# MKV31F51212 register map
Vendor: Freescale Semiconductor, Inc.; Series: Kinetis_V; File version: 1.6
CPU: CM4 r0p1, little endian, no MPU, FPU, VTOR, 4 interrupt priority bits
Registers are 32-bit, read-write, reset 0x0 unless marked. A register's access mark holds for its fields unless they carry their own. Offsets are from the block's base; [hi:lo] are bit positions; {n}, {i} and the like mark numbered series.

## FTFA_FlashConfig — Flash configuration field
Base 0x00000400; register names take the prefix NV_
0x00 BACKKEY3 8-bit ro reset 0xFF — Backdoor Comparison Key 3.
  [7:0] KEY — Backdoor Comparison Key.
0x01 BACKKEY2 8-bit ro reset 0xFF — Backdoor Comparison Key 2.
  [7:0] KEY — Backdoor Comparison Key.
0x02 BACKKEY1 8-bit ro reset 0xFF — Backdoor Comparison Key 1.
  [7:0] KEY — Backdoor Comparison Key.
0x03 BACKKEY0 8-bit ro reset 0xFF — Backdoor Comparison Key 0.
  [7:0] KEY — Backdoor Comparison Key.
0x04 BACKKEY7 8-bit ro reset 0xFF — Backdoor Comparison Key 7.
  [7:0] KEY — Backdoor Comparison Key.
0x05 BACKKEY6 8-bit ro reset 0xFF — Backdoor Comparison Key 6.
  [7:0] KEY — Backdoor Comparison Key.
0x06 BACKKEY5 8-bit ro reset 0xFF — Backdoor Comparison Key 5.
  [7:0] KEY — Backdoor Comparison Key.
0x07 BACKKEY4 8-bit ro reset 0xFF — Backdoor Comparison Key 4.
  [7:0] KEY — Backdoor Comparison Key.
0x08 FPROT3 8-bit ro reset 0xFF — Non-volatile P-Flash Protection 1 - Low Register
  [7:0] PROT — P-Flash Region Protect
0x09 FPROT2 8-bit ro reset 0xFF — Non-volatile P-Flash Protection 1 - High Register
  [7:0] PROT — P-Flash Region Protect
0x0A FPROT1 8-bit ro reset 0xFF — Non-volatile P-Flash Protection 0 - Low Register
  [7:0] PROT — P-Flash Region Protect
0x0B FPROT0 8-bit ro reset 0xFF — Non-volatile P-Flash Protection 0 - High Register
  [7:0] PROT — P-Flash Region Protect
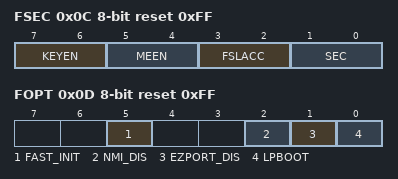
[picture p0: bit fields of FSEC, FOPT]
0x0C FSEC 8-bit ro reset 0xFF — Non-volatile Flash Security Register
  [7:6] KEYEN — Backdoor Key Security Enable
    2=Backdoor key access enabled; 3=Backdoor key access disabled
  [5:4] MEEN
    2=Mass erase is disabled; 3=Mass erase is enabled
  [3:2] FSLACC — Freescale Failure Analysis Access Code
    2=Freescale factory access denied; 3=Freescale factory access granted
  [1:0] SEC — Flash Security
    2=MCU security status is unsecure; 3=MCU security status is secure
0x0D FOPT 8-bit ro reset 0xFF — Non-volatile Flash Option Register
  [5] FAST_INIT
    0=Slower initialization; 1=Fast Initialization
  [2] NMI_DIS
    0=NMI interrupts are always blocked; 1=NMI_b pin/interrupts reset default to enabled
  [1] EZPORT_DIS
    0=EzPort operation is disabled; 1=EzPort operation is enabled
  [0] LPBOOT
    0=Low-power boot; 1=Normal boot

## DMAMUX — DMA channel multiplexor
Base 0x40021000; register names take the prefix DMAMUX_
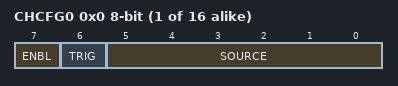
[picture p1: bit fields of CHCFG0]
{0x0+i} CHCFG{i} (i=0..15) 8-bit — Channel Configuration register
  [7] ENBL — DMA Channel Enable
    0=DMA channel is disabled. This mode is primarily used during configuration of the DMAMux. The DMA has separate channel enables/disables, which should be used to disable or reconfigure a DMA channel.; 1=DMA channel is enabled
  [6] TRIG — DMA Channel Trigger Enable
    0=Triggering is disabled. If triggering is disabled and ENBL is set, the DMA Channel will simply route the specified source to the DMA channel. (Normal mode); 1=Triggering is enabled. If triggering is enabled and ENBL is set, the DMAMUX is in Periodic Trigger mode.
  [5:0] SOURCE — DMA Channel Source (Slot)

## DAC0 — 12-Bit Digital-to-Analog Converter
Base 0x4003F000; register names take the prefix DAC0_
{0x0+2i} DAT{i}L (i=0..15) 8-bit — DAC Data Low Register
  [7:0] DATA0
{0x1+2i} DAT{i}H (i=0..15) 8-bit — DAC Data High Register
  [3:0] DATA1
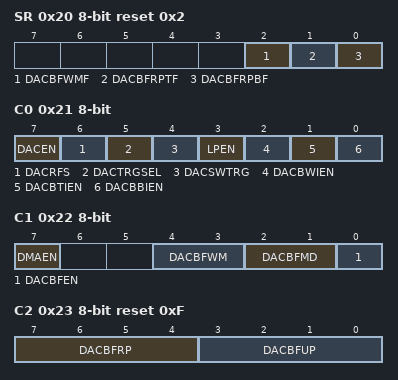
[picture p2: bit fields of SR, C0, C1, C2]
0x20 SR 8-bit reset 0x2 — DAC Status Register
  [2] DACBFWMF — DAC Buffer Watermark Flag
    0=The DAC buffer read pointer has not reached the watermark level; 1=The DAC buffer read pointer has reached the watermark level
  [1] DACBFRPTF — DAC Buffer Read Pointer Top Position Flag
    0=The DAC buffer read pointer is not zero; 1=The DAC buffer read pointer is zero
  [0] DACBFRPBF — DAC Buffer Read Pointer Bottom Position Flag
    0=The DAC buffer read pointer is not equal to C2[DACBFUP]; 1=The DAC buffer read pointer is equal to C2[DACBFUP]
0x21 C0 8-bit — DAC Control Register
  [7] DACEN — DAC Enable
    0=The DAC system is disabled; 1=The DAC system is enabled
  [6] DACRFS — DAC Reference Select
    0=The DAC selects DACREF_1 as the reference voltage; 1=The DAC selects DACREF_2 as the reference voltage
  [5] DACTRGSEL — DAC Trigger Select
    0=The DAC hardware trigger is selected; 1=The DAC software trigger is selected
  [4] DACSWTRG wo — DAC Software Trigger
    0=The DAC soft trigger is not valid; 1=The DAC soft trigger is valid
  [3] LPEN — DAC Low Power Control
    0=High-Power mode; 1=Low-Power mode
  [2] DACBWIEN — DAC Buffer Watermark Interrupt Enable
    0=The DAC buffer watermark interrupt is disabled; 1=The DAC buffer watermark interrupt is enabled
  [1] DACBTIEN — DAC Buffer Read Pointer Top Flag Interrupt Enable
    0=The DAC buffer read pointer top flag interrupt is disabled; 1=The DAC buffer read pointer top flag interrupt is enabled
  [0] DACBBIEN — DAC Buffer Read Pointer Bottom Flag Interrupt Enable
    0=The DAC buffer read pointer bottom flag interrupt is disabled; 1=The DAC buffer read pointer bottom flag interrupt is enabled
0x22 C1 8-bit — DAC Control Register 1
  [7] DMAEN — DMA Enable Select
    0=DMA is disabled; 1=DMA is enabled. When DMA is enabled, the DMA request will be generated by original interrupts. The interrupts will not be presented on this module at the same time.
  [4:3] DACBFWM — DAC Buffer Watermark Select
    0=In normal mode, 1 word . In FIFO mode, 2 or less than 2 data remaining in FIFO will set watermark status bit.; 1=In normal mode, 2 words . In FIFO mode, Max/4 or less than Max/4 data remaining in FIFO will set watermark status bit.; 2=In normal mode, 3 words . In FIFO mode, Max/2 or less than Max/2 data remaining in FIFO will set watermark status bit.; 3=In normal mode, 4 words . In FIFO mode, Max-2 or less than Max-2 data remaining in FIFO will set watermark status bit.
  [2:1] DACBFMD — DAC Buffer Work Mode Select
    0=Normal mode; 1=Swing mode; 2=One-Time Scan mode; 3=FIFO mode
  [0] DACBFEN — DAC Buffer Enable
    0=Buffer read pointer is disabled. The converted data is always the first word of the buffer.; 1=Buffer read pointer is enabled. The converted data is the word that the read pointer points to. It means converted data can be from any word of the buffer.
0x23 C2 8-bit reset 0xF — DAC Control Register 2
  [7:4] DACBFRP — DAC Buffer Read Pointer
  [3:0] DACBFUP — DAC Buffer Upper Limit

## DAC1 — 12-Bit Digital-to-Analog Converter
Base 0x40028000; register names take the prefix DAC1_
Registers as DAC0.

## Notices in the file
Redistribution and use in source and binary forms, with or without modification,
are permitted provided that the following conditions are met:
o Redistributions of source code must retain the above copyright notice, this list
of conditions and the following disclaimer.
o Redistributions in binary form must reproduce the above copyright notice, this
list of conditions and the following disclaimer in the documentation and/or
other materials provided with the distribution.
o Neither the name of Freescale Semiconductor, Inc. nor the names of its
contributors may be used to endorse or promote products derived from this
software without specific prior written permission.
THIS SOFTWARE IS PROVIDED BY THE COPYRIGHT HOLDERS AND CONTRIBUTORS "AS IS" AND
ANY EXPRESS OR IMPLIED WARRANTIES, INCLUDING, BUT NOT LIMITED TO, THE IMPLIED
WARRANTIES OF MERCHANTABILITY AND FITNESS FOR A PARTICULAR PURPOSE ARE
DISCLAIMED. IN NO EVENT SHALL THE COPYRIGHT HOLDER OR CONTRIBUTORS BE LIABLE FOR
ANY DIRECT, INDIRECT, INCIDENTAL, SPECIAL, EXEMPLARY, OR CONSEQUENTIAL DAMAGES
(INCLUDING, BUT NOT LIMITED TO, PROCUREMENT OF SUBSTITUTE GOODS OR SERVICES;
LOSS OF USE, DATA, OR PROFITS; OR BUSINESS INTERRUPTION) HOWEVER CAUSED AND ON
ANY THEORY OF LIABILITY, WHETHER IN CONTRACT, STRICT LIABILITY, OR TORT
(INCLUDING NEGLIGENCE OR OTHERWISE) ARISING IN ANY WAY OUT OF THE USE OF THIS
SOFTWARE, EVEN IF ADVISED OF THE POSSIBILITY OF SUCH DAMAGE.
